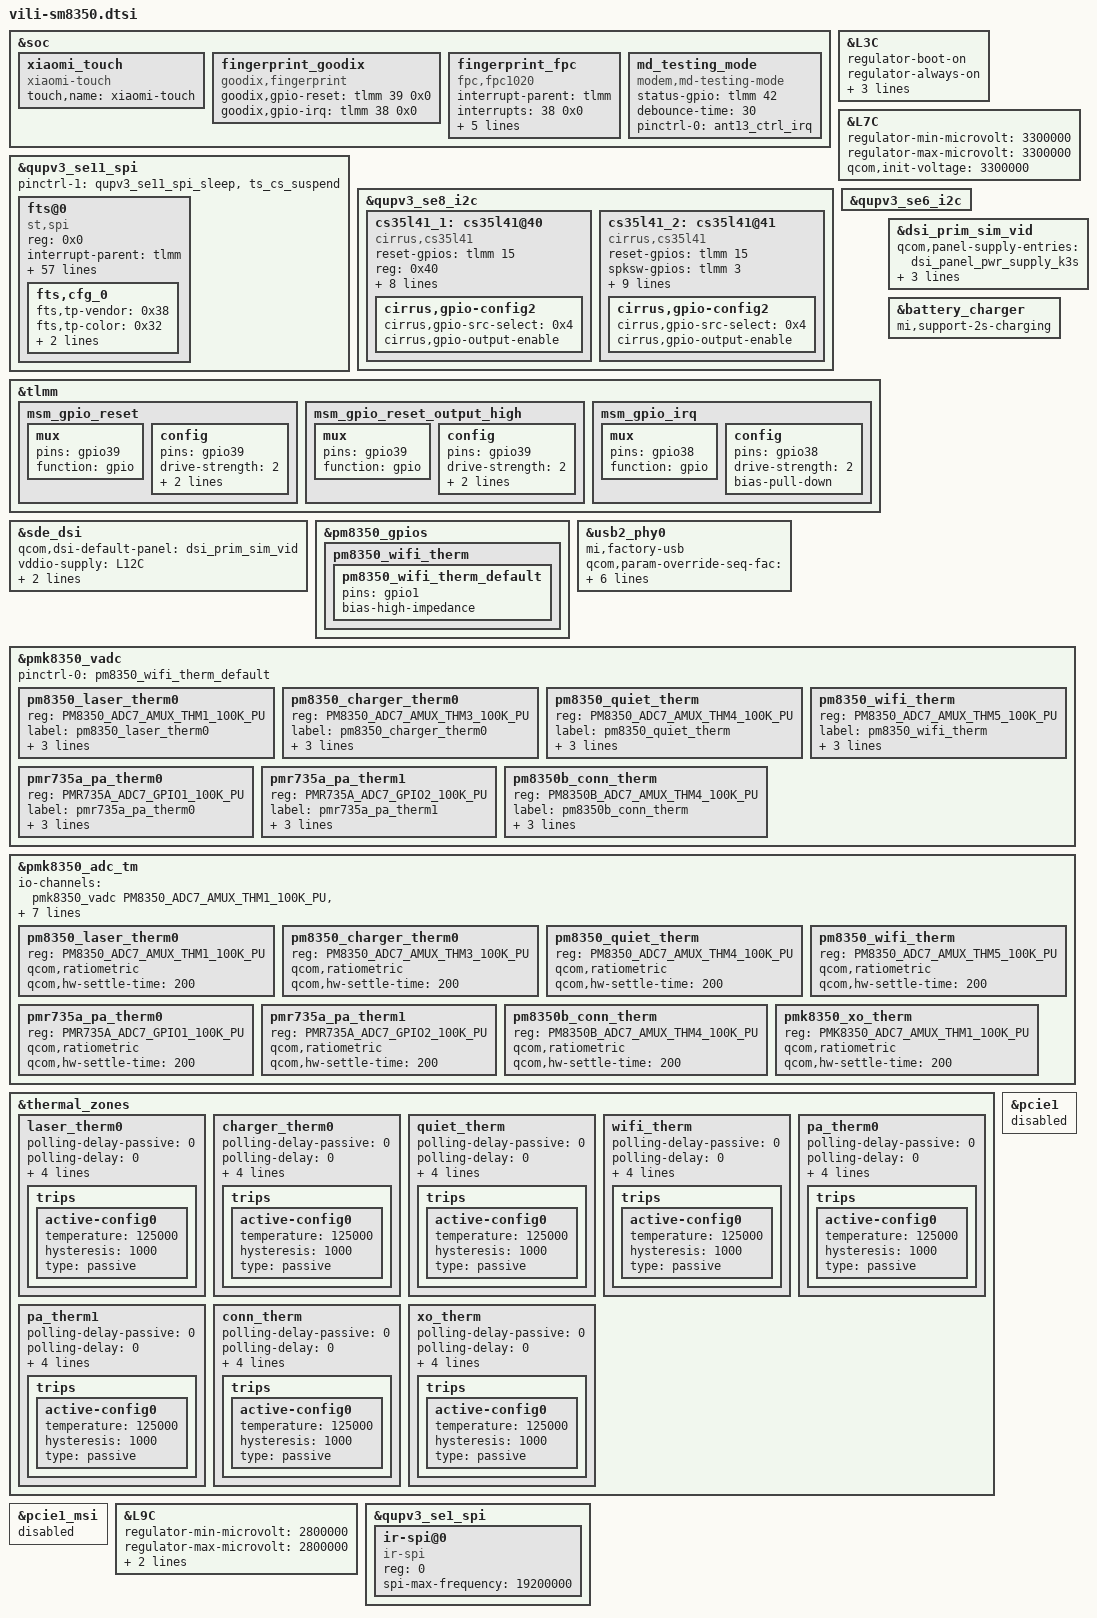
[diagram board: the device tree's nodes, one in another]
/*
this file is for attribution only of mars
And public attribution of xiaomi platforms(like venus and so and)
*/

#include "vili-pinctrl.dtsi"
#include "xiaomi-sm8350-common.dtsi"
#include "vili-audio-overlay.dtsi"
#include "camera/vili-sm8350-camera-sensor.dtsi"

&soc {
	xiaomi_touch {
		compatible = "xiaomi-touch";
		status = "ok";
		touch,name = "xiaomi-touch";
	};

        fingerprint_goodix {
                status = "ok";
                compatible = "goodix,fingerprint";
                goodix,gpio-reset = <&tlmm 39 0x0>;
                goodix,gpio-irq = <&tlmm 38 0x0>;
        };

	fingerprint_fpc {
		status = "ok";
		compatible = "fpc,fpc1020";
		interrupt-parent = <&tlmm>;
		interrupts = <38 0x0>;
		fpc,gpio_rst    = <&tlmm 39 0x0>;
		fpc,gpio_irq    = <&tlmm 38 0x0>;
		pinctrl-names = "fpc1020_reset_reset",
						"fpc1020_reset_active",
						"fpc1020_irq_active";

		pinctrl-0 = <&msm_gpio_reset>;
		pinctrl-1 = <&msm_gpio_reset_output_high>;
		pinctrl-2 = <&msm_gpio_irq>;
	};

	md_testing_mode {
		compatible = "modem,md-testing-mode";
		status-gpio = <&tlmm 42 0x00>;
		debounce-time = <30>;
		pinctrl-names = "default";
		pinctrl-0 = <&ant13_ctrl_irq>;
	};

};

&L3C {
        regulator-boot-on;
        regulator-always-on;
        qcom,init-voltage = <3300000>;
};

&L7C {
	regulator-min-microvolt = <3300000>;
	regulator-max-microvolt = <3300000>;
	qcom,init-voltage = <3300000>;
};

&qupv3_se11_spi {
	status = "ok";
	pinctrl-1 = <&qupv3_se11_spi_sleep &ts_cs_suspend>;
	fts@0 {
		status = "ok";
		compatible = "st,spi";
		reg = <0x0>;
		interrupt-parent = <&tlmm>;
		interrupts = <23 0x2008>;
		pinctrl-names = "pmx_ts_active", "pmx_ts_suspend";
		pinctrl-0 = <&mi_ts_active>;
		pinctrl-1 = <&ts_int_suspend &ts_reset_suspend>;
		avdd-supply = <&L7C>;
		vdd-supply = <&L2C>;
		panel = <&dsi_k3s_42_02_0a_dsc_cmd>;
		fts,config-array-size = <1>;
		fts,pwr-reg-name = "avdd";
		fts,bus-reg-name = "vdd";
		fts,irq-gpio = <&tlmm 23 0x2008>;
		fts,irq-gpio-name = "fts_irq";
		fts,reset-gpio-enable;
		fts,reset-gpio = <&tlmm 22 0x00>;
		fts,reset-gpio-name = "fts_rst";
		fts,irq-flags = <0x2008>;
		fts,x-max = <10800>;
		fts,y-max = <24000>;
		spi-max-frequency = <7000000>;
		fts,default-fw-name = "st_fts_k3s.ftb";
		/*
		fts,touch-up-threshold-min = <40>;
		fts,touch-up-threshold-max = <120>;
		fts,touch-up-threshold-def = <80>;
		fts,touch-tolerance-min = <5>;
		fts,touch-tolerance-max = <35>;
		fts,touch-tolerance-def = <25>;
		*/
		fts,non-curved-display = <1>;
		fts,support-super-resolution = <1>;
		fts,touch-follow-performance-def = <3>;
		fts,touch-tap-sensitivity-def = <4>;
		fts,touch-aim-sensitivity-def = <3>;
		fts,touch-tap-stability-def = <3>;
		fts,cornerfilter-area-step1 = <100>;
		fts,cornerfilter-area-step2 = <170>;
		fts,cornerfilter-area-step3 = <250>;
		fts,touch-deadzone-filter-ver = <2 0 0 0 0 0 0 0
										2 1 0 0 0 0 0 0
										2 2 0 0 0 0 0 0
										2 3 0 0 0 0 0 0>;
		fts,touch-deadzone-filter-hor = <2 0 0 0 0 0 0 0
										2 1 0 0 0 0 0 0
										2 2 0 0 0 0 0 0
										2 3 0 0 0 0 0 0>;
		fts,touch-edgezone-filter-ver = <1 0 0 0 0 0 0 0
										1 1 0 0 0 0 0 0
										1 2 0 0 40 2399 0 0
										1 3 1039 0 1079 2399 0 0>;
		fts,touch-edgezone-filter-hor = <1 0 0 0 1079 40 0 0
										1 1 0 2359 1079 2399 0 0
										1 2 0 0 40 2399 0 0
										1 3 1039 0 1079 2399 0 0>;
		fts,touch-cornerzone-filter-ver = <0 0 0 0 0 0 0 0
										0 1 0 0 0 0 0 0
										0 2 0 2099 150 2399 0 0
										0 3 929 2099 1079 2399 0 0>;
		fts,touch-cornerzone-filter-hor1 = <0 0 0 0 150 150 0 0
										0 1 0 0 0 0 0 0
										0 2 0 2249 150 2399 0 0
										0 3 0 0 0 0 0 0>;
		fts,touch-cornerzone-filter-hor2 = <0 0 0 0 0 0 0 0
										0 1 929 0 1079 150 0 0
										0 2 0 0 0 0 0 0
										0 3 929 2249 1079 2399 0 0>;
		fts,touch-normal-deadzone-filter-hor = <2 0 0 0 1079 0 0 0
										2 1 0 2399 1079 2399 0 0
										2 2 0 0 0 2399 0 0
										2 3 1079 0 1079 2399 0 0>;
		fts,touch-normal-edgezone-filter-hor = <1 0 0 0 1079 30 0 0
										1 1 0 2369 1079 2399 0 0
										1 2 0 0 30 2399 0 0
										1 3 1049 0 1079 2399 0 0>;
		fts,touch-normal-cornerzone-filter-hor1 = <0 0 0 0 170 170 0 0
										0 1 0 0 0 0 0 0
										0 2 0 2229 170 2399 0 0
										0 3 0 0 0 0 0 0>;
		fts,touch-normal-cornerzone-filter-hor2 = <0 0 0 0 0 0 0 0
										0 1 909 0 1079 170 0 0
										0 2 0 0 0 0 0 0
										0 3 909 2229 1079 2399 0 0>;
		fts,touch-follow-performance = <10 15 1
										8 15 1
										6 15 1
										4 15 1
										2 15 1>;
		fts,touch-tap-sensitivity = <160 150 140 120 100>;
		fts,touch-aim-sensitivity = <10 8 6 4 2>;
		fts,touch-tap-stability = <8 12 15 18 25>;
		fts,touch-expert-array = <6 15 1 120 6 15
								  2 15 1 120 4 15
								  4 15 1 120 2 15>;
		fts,cfg_0 {
			fts,tp-vendor = <0x38>;
			fts,tp-color = <0x32>;
			fts,fw-name = "st_fts_k3s.ftb";
			fts,limit-name = "stm_fts_production_limits.csv";
		};
	};
};


&qupv3_se8_i2c {
	status = "ok";
	cs35l41_1: cs35l41@40 {
		status = "ok";
		compatible = "cirrus,cs35l41";
		reset-gpios = <&tlmm 15 0>;
		reg = <0x40>;
		interrupt-parent = <&tlmm>;
		interrupts = <44 8>;
		cirrus,temp-warn_threshold = <3>;
		cirrus,boost-peak-milliamp = <4000>;
		cirrus,boost-ind-nanohenry = <1000>;
		cirrus,boost-cap-microfarad = <15>;
		cirrus,asp-sdout-hiz = <3>;
		sound-name-prefix = "RCV";
		cirrus,gpio-config2 {
			cirrus,gpio-src-select = <0x4>;
			cirrus,gpio-output-enable;
		};
	};
	cs35l41_2: cs35l41@41 {
		compatible = "cirrus,cs35l41";
		reset-gpios = <&tlmm 15 0>;
		spksw-gpios = <&tlmm 3 0>;
		reg = <0x41>;
		interrupt-parent = <&tlmm>;
		interrupts = <79 8>;
		cirrus,temp-warn_threshold = <3>;
		cirrus,boost-peak-milliamp = <4000>;
		cirrus,boost-ind-nanohenry = <1000>;
		cirrus,boost-cap-microfarad = <15>;
		cirrus,asp-sdout-hiz = <3>;
		cirrus,right-channel-amp;
		cirrus,gpio-config2 {
			cirrus,gpio-src-select = <0x4>;
			cirrus,gpio-output-enable;
		};
	};
};

&qupv3_se6_i2c {
	status = "ok";
};

&L3C {
	regulator-min-microvolt = <3300000>;
	regulator-max-microvolt = <3300000>;
	qcom,init-voltage = <3300000>;
};

&tlmm {
		/* FP_RESET_N */
	msm_gpio_reset: msm_gpio_reset {
		mux {
			pins = "gpio39";
			function = "gpio";
		};
		config {
			pins = "gpio39";
			drive-strength = <2>;
			bias-disable;
			output-low;
		};
	};
		/* FP_RESET_N, state device active*/
	msm_gpio_reset_output_high: msm_gpio_reset_output_high {
		mux {
			pins = "gpio39";
			function = "gpio";
		};
		config {
			pins = "gpio39";
			drive-strength = <2>;
			bias-disable;
			output-high;
		};
	};
		/* FP_INT_N */
	msm_gpio_irq: msm_gpio_irq {
		mux {
			pins = "gpio38";
			function = "gpio";
		};
		config {
			pins = "gpio38";
			drive-strength = <2>;
			bias-pull-down;
		};
	};
};


&dsi_prim_sim_vid {
	qcom,panel-supply-entries = <&dsi_panel_pwr_supply_k3s>;
	qcom,mdss-dsi-bl-pmic-control-type = "bl_ctrl_dcs";
	qcom,platform-reset-gpio = <&tlmm 24 0>;
};

&sde_dsi {
	qcom,dsi-default-panel = <&dsi_prim_sim_vid>;
	vddio-supply = <&L12C>;
	dvdd-supply = <&L1D>;
	vdd-supply = <&L13C>;
};

&pm8350_gpios {
	pm8350_wifi_therm {
		pm8350_wifi_therm_default: pm8350_wifi_therm_default {
			pins = "gpio1";
			bias-high-impedance;
		};
	};
};

&usb2_phy0 {
	mi,factory-usb;
	qcom,param-override-seq-fac =
	<0xa5 0x6c	/* override_x0 */
	 0x0e 0x70	/* override_x1 */
	 0x04 0x74>;	/* override x2 */
	qcom,param-override-seq =
	<0x07 0x6c	/* override_x0 */
	 0x0e 0x70	/* override_x1 */
	 0x04 0x74>;	/* override x2 */
	mi,usb-distinguish-host-deivice;
	qcom,param-override-seq-host =
	<0x07 0x6c	/* override_x0_host */
	 0x0b 0x70	/* override_x1_host */
	 0x04 0x74>;	/* override x2_host */
};

&battery_charger {
	mi,support-2s-charging;
};

&pmk8350_vadc {
	pinctrl-names = "default";
	pinctrl-0 = <&pm8350_wifi_therm_default>;

	pm8350_laser_therm0 {
		reg = <PM8350_ADC7_AMUX_THM1_100K_PU>;
		label = "pm8350_laser_therm0";
		qcom,ratiometric;
		qcom,hw-settle-time = <200>;
		qcom,pre-scaling = <1 1>;
	};

        pm8350_charger_therm0 {
		reg = <PM8350_ADC7_AMUX_THM3_100K_PU>;
		label = "pm8350_charger_therm0";
		qcom,ratiometric;
		qcom,hw-settle-time = <200>;
		qcom,pre-scaling = <1 1>;
	};
        pm8350_quiet_therm {
		reg = <PM8350_ADC7_AMUX_THM4_100K_PU>;
		label = "pm8350_quiet_therm";
		qcom,ratiometric;
		qcom,hw-settle-time = <200>;
		qcom,pre-scaling = <1 1>;
	};
        pm8350_wifi_therm {
		reg = <PM8350_ADC7_AMUX_THM5_100K_PU>;
		label = "pm8350_wifi_therm";
		qcom,ratiometric;
		qcom,hw-settle-time = <200>;
		qcom,pre-scaling = <1 1>;
	};
        pmr735a_pa_therm0 {
		reg = <PMR735A_ADC7_GPIO1_100K_PU>;
		label = "pmr735a_pa_therm0";
		qcom,ratiometric;
		qcom,hw-settle-time = <200>;
		qcom,pre-scaling = <1 1>;
	};
       	pmr735a_pa_therm1 {
		reg = <PMR735A_ADC7_GPIO2_100K_PU>;
		label = "pmr735a_pa_therm1";
	        qcom,ratiometric;
		qcom,hw-settle-time = <200>;
		qcom,pre-scaling = <1 1>;
        };
        pm8350b_conn_therm {
		reg = <PM8350B_ADC7_AMUX_THM4_100K_PU>;
		label = "pm8350b_conn_therm";
		qcom,ratiometric;
		qcom,hw-settle-time = <200>;
		qcom,pre-scaling = <1 1>;
        };
};

&pmk8350_adc_tm {
	io-channels = <&pmk8350_vadc PM8350_ADC7_AMUX_THM1_100K_PU>,//laser_therm0
			<&pmk8350_vadc PM8350_ADC7_AMUX_THM3_100K_PU>,//charge_therm0
			<&pmk8350_vadc PM8350_ADC7_AMUX_THM4_100K_PU>,//quiet_therm
                        <&pmk8350_vadc PM8350_ADC7_AMUX_THM5_100K_PU>,//wifi_therm
			<&pmk8350_vadc PMR735A_ADC7_GPIO1_100K_PU>,//pa_therm0
			<&pmk8350_vadc PMR735A_ADC7_GPIO2_100K_PU>,//pa_therm1
                        <&pmk8350_vadc PM8350B_ADC7_AMUX_THM4_100K_PU>,//conn_therm
			<&pmk8350_vadc PMK8350_ADC7_AMUX_THM1_100K_PU>;//xo_therm

	pm8350_laser_therm0 {
		reg = <PM8350_ADC7_AMUX_THM1_100K_PU>;
		qcom,ratiometric;
		qcom,hw-settle-time = <200>;
	};

	pm8350_charger_therm0 {
		reg = <PM8350_ADC7_AMUX_THM3_100K_PU>;
		qcom,ratiometric;
		qcom,hw-settle-time = <200>;
	};

	pm8350_quiet_therm {
		reg = <PM8350_ADC7_AMUX_THM4_100K_PU>;
		qcom,ratiometric;
		qcom,hw-settle-time = <200>;
	};

	pm8350_wifi_therm {
		reg = <PM8350_ADC7_AMUX_THM5_100K_PU>;
		qcom,ratiometric;
		qcom,hw-settle-time = <200>;
	};

	pmr735a_pa_therm0 {
		reg = <PMR735A_ADC7_GPIO1_100K_PU>;
		qcom,ratiometric;
		qcom,hw-settle-time = <200>;
	};

	pmr735a_pa_therm1 {
		reg = <PMR735A_ADC7_GPIO2_100K_PU>;
		qcom,ratiometric;
		qcom,hw-settle-time = <200>;
	};

	pm8350b_conn_therm {
		reg = <PM8350B_ADC7_AMUX_THM4_100K_PU>;
		qcom,ratiometric;
		qcom,hw-settle-time = <200>;
	};

	pmk8350_xo_therm {
		reg = <PMK8350_ADC7_AMUX_THM1_100K_PU>;
		qcom,ratiometric;
		qcom,hw-settle-time = <200>;
	};
};

&thermal_zones {
	laser_therm0 {
		polling-delay-passive = <0>;
		polling-delay = <0>;
		thermal-governor = "user_space";
		thermal-sensors = <&pmk8350_adc_tm PM8350_ADC7_AMUX_THM1_100K_PU>;
		wake-capable-sensor;
		trips {
			active-config0 {
				temperature = <125000>;
				hysteresis = <1000>;
				type = "passive";
			};
		};
	};

	charger_therm0 {
                polling-delay-passive = <0>;
                polling-delay = <0>;
                thermal-governor = "user_space";
                thermal-sensors = <&pmk8350_adc_tm PM8350_ADC7_AMUX_THM3_100K_PU>;
                wake-capable-sensor;
                trips {
                        active-config0 {
                                temperature = <125000>;
                                hysteresis = <1000>;
                                type = "passive";
                        };
                };
        };

	quiet_therm {
		polling-delay-passive = <0>;
		polling-delay = <0>;
		thermal-governor = "user_space";
		thermal-sensors = <&pmk8350_adc_tm PM8350_ADC7_AMUX_THM4_100K_PU>;
		wake-capable-sensor;
		trips {
			active-config0 {
				temperature = <125000>;
				hysteresis = <1000>;
				type = "passive";
			};
		};
	};

        wifi_therm {
                polling-delay-passive = <0>;
                polling-delay = <0>;
                thermal-governor = "user_space";
                thermal-sensors = <&pmk8350_adc_tm PM8350_ADC7_AMUX_THM5_100K_PU>;
                wake-capable-sensor;
                trips {
                        active-config0 {
                                temperature = <125000>;
                                hysteresis = <1000>;
                                type = "passive";
                        };
                };
        };

	pa_therm0 {
		polling-delay-passive = <0>;
		polling-delay = <0>;
		thermal-governor = "user_space";
		thermal-sensors = <&pmk8350_adc_tm PMR735A_ADC7_GPIO1_100K_PU>;
		wake-capable-sensor;
		trips {
			active-config0 {
				temperature = <125000>;
				hysteresis = <1000>;
				type = "passive";
			};
		};
	};

	pa_therm1 {
                polling-delay-passive = <0>;
                polling-delay = <0>;
                thermal-governor = "user_space";
                thermal-sensors = <&pmk8350_adc_tm PMR735A_ADC7_GPIO2_100K_PU>;
                wake-capable-sensor;
                trips {
                        active-config0 {
                                temperature = <125000>;
                                hysteresis = <1000>;
                                type = "passive";
                        };
                };
        };

        conn_therm {
		polling-delay-passive = <0>;
		polling-delay = <0>;
		thermal-governor = "user_space";
		thermal-sensors = <&pmk8350_adc_tm PM8350B_ADC7_AMUX_THM4_100K_PU>;
		wake-capable-sensor;
		trips {
			active-config0 {
				temperature = <125000>;
				hysteresis = <1000>;
				type = "passive";
			};
		};
	};
	xo_therm {
		polling-delay-passive = <0>;
		polling-delay = <0>;
		thermal-governor = "user_space";
		thermal-sensors = <&pmk8350_adc_tm PMK8350_ADC7_AMUX_THM1_100K_PU>;
		wake-capable-sensor;
		trips {
			active-config0 {
				temperature = <125000>;
				hysteresis = <1000>;
				type = "passive";
			};
		};
	};
};

&pcie1 {
	status = "disabled";
};

&pcie1_msi {
	status = "disabled";
};

&L9C {
        regulator-min-microvolt = <2800000>;
        regulator-max-microvolt = <2800000>;
        qcom,init-voltage = <2800000>;
        regulator-always-on;
};

&qupv3_se1_spi {
        status = "ok";
        ir-spi@0 {
                compatible = "ir-spi";
                reg = <0>;
                spi-max-frequency = <19200000>;
                status = "ok";
        };
};
